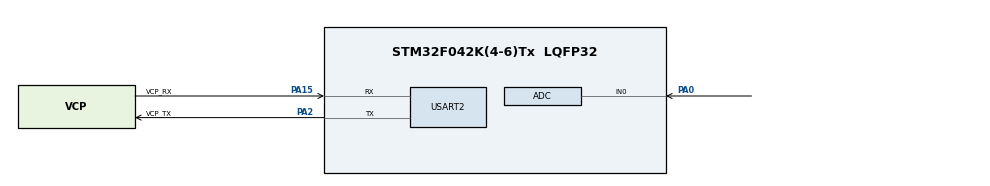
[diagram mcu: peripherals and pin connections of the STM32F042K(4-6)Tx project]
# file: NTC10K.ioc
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Dma.ADC.0.Direction=DMA_PERIPH_TO_MEMORY
Dma.ADC.0.Instance=DMA1_Channel1
Dma.ADC.0.MemDataAlignment=DMA_MDATAALIGN_HALFWORD
Dma.ADC.0.MemInc=DMA_MINC_ENABLE
Dma.ADC.0.Mode=DMA_CIRCULAR
Dma.ADC.0.PeriphDataAlignment=DMA_PDATAALIGN_HALFWORD
Dma.ADC.0.PeriphInc=DMA_PINC_DISABLE
Dma.ADC.0.Priority=DMA_PRIORITY_LOW
Dma.Request0=ADC
Mcu.Family=STM32F0
Mcu.Name=STM32F042K(4-6)Tx
Mcu.Package=LQFP32
NVIC.DMA1_Channel1_IRQn=true\:0\:0\:false\:false\:true\:false\:true
NVIC.TIM3_IRQn=true\:0\:0\:false\:false\:true\:true\:true
PA0.Mode=IN0
PA0.Signal=ADC_IN0
PA13.GPIO_Label=SWDIO
PA13.Mode=Serial_Wire
PA13.Signal=SYS_SWDIO
PA14.GPIO_Label=SWCLK
PA14.Mode=Serial_Wire
PA14.Signal=SYS_SWCLK
PA15.GPIO_Label=VCP_RX
PA15.Mode=Asynchronous
PA15.Signal=USART2_RX
PA2.GPIO_Label=VCP_TX
PA2.Mode=Asynchronous
PA2.Signal=USART2_TX
PF0-OSC_IN.GPIO_Label=MCO
PF0-OSC_IN.Mode=HSE-External-Clock-Source
PF0-OSC_IN.Signal=RCC_OSC_IN
ProjectManager.HeapSize=0x200
ProjectManager.StackSize=0x400
ProjectManager.TargetToolchain=STM32CubeIDE
TIM3.Period=1000-1
TIM3.Prescaler=800-1
USART2.VirtualMode-Asynchronous=VM_ASYNC
VP_TIM3_VS_ClockSourceINT.Mode=Internal
board=NUCLEO-F042K6

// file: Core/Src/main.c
/* USER CODE BEGIN Header */
/**
 ******************************************************************************
 * @file           : main.c
 * @brief          : Main program body
 ******************************************************************************
 * @attention
 *
 * <h2><center>&copy; Copyright (c) 2021 STMicroelectronics.
 * All rights reserved.</center></h2>
 *
 * This software component is licensed by ST under BSD 3-Clause license,
 * the "License"; You may not use this file except in compliance with the
 * License. You may obtain a copy of the License at:
 *                        opensource.org/licenses/BSD-3-Clause
 *
 ******************************************************************************
 */
/* USER CODE END Header */
#include "main.h"
#include "adc.h"
#include "dma.h"
#include "tim.h"
#include "usart.h"
#include "gpio.h"

/* USER CODE BEGIN Includes */
#include <math.h>
/* USER CODE END Includes */

/* USER CODE BEGIN PV */
/* adc vars */
uint16_t ADC_Raw[1];
/* ntc vars */
float Ntc_Tmp = 0;
uint16_t Ntc_R;
/* sheduler vars */
uint8_t Sch_100ms = 255;

/* R1 resistance */
#define NTC_UP_R 10000.0f
/* constants of Steinhart-Hart equation */
#define A 0.001111f
#define B 0.000237987f
#define C 0.000000065f
/* USER CODE END PV */

void SystemClock_Config(void);
/* USER CODE BEGIN PFP */
#define FILTER_SMA_ORDER 12
uint16_t Filter_Buffer[FILTER_SMA_ORDER] = { 0 };
/**
 * @brief Simple Moving Average (SMA) filter.
 * @note Before use define filter order.
 * @param[in] Input raw (unfiltered) value.
 * @retval Return filtered data.
 */
uint16_t Filter_SMA(uint16_t For_Filtered);
/* USER CODE END PFP */

/* USER CODE BEGIN 0 */
/**
 * @brief Simple Moving Average (SMA) filter.
 * @note Before use define filter order.
 * @param[in] Input raw (unfiltered) value.
 * @retval Return filtered data.
 */
uint16_t Filter_SMA(uint16_t For_Filtered)
{
    /* Load new value */
    Filter_Buffer[FILTER_SMA_ORDER - 1] = For_Filtered;
    /* For output value */
    uint32_t Output = 0;
    /* Sum */
    for (uint8_t i = 0; i < FILTER_SMA_ORDER; i++) {
        Output += Filter_Buffer[i];
    }
    /* Divide */
    Output /= FILTER_SMA_ORDER;
    /* Left Shift */
    for (uint8_t i = 0; i < FILTER_SMA_ORDER; i++) {
        Filter_Buffer[i] = Filter_Buffer[i + 1];
    }
    /* Return filtered value */
    return (uint16_t) Output;
}
/* USER CODE END 0 */

int main(void)
{

  /* MCU Configuration--------------------------------------------------------*/

  /* Reset of all peripherals, Initializes the Flash interface and the Systick. */
  HAL_Init();

  /* Configure the system clock */
  SystemClock_Config();

  /* Initialize all configured peripherals */
  MX_GPIO_Init();
  MX_DMA_Init();
  MX_ADC_Init();
  MX_USART2_UART_Init();
  MX_TIM3_Init();
  /* USER CODE BEGIN 2 */
    /* adc calibration */
    HAL_ADCEx_Calibration_Start(&hadc);
    /* adc dma start */
    HAL_ADC_Start_DMA(&hadc, (uint32_t*) ADC_Raw, 1);
    /* timer 3 (f=1Hz, T=1000ms start */
    HAL_TIM_Base_Start_IT(&htim3);
  /* USER CODE END 2 */

  /* Infinite loop */
  /* USER CODE BEGIN WHILE */
    while (1) {
        if (Sch_100ms) {
            /* get adc value */
            HAL_ADC_Start_IT(&hadc);
            /* filtering (sma) */
            uint16_t Ntc_Temp_ADC = Filter_SMA(ADC_Raw[0]);
            /* calc. ntc resistance */
            Ntc_R = ((NTC_UP_R) / ((4095.0 / Ntc_Temp_ADC) - 1));
            /* temp */
            float Ntc_Ln = log(Ntc_R);
            /* calc. temperature */
            Ntc_Tmp = (1.0 / (A + B * Ntc_Ln + C * Ntc_Ln * Ntc_Ln * Ntc_Ln))
                    - 273.15;
            /* nullify */
            Sch_100ms = 0;
        }
    /* USER CODE END WHILE */

    }
}

void SystemClock_Config(void)
{
  RCC_OscInitTypeDef RCC_OscInitStruct = {0};
  RCC_ClkInitTypeDef RCC_ClkInitStruct = {0};

  /** Initializes the RCC Oscillators according to the specified parameters
  * in the RCC_OscInitTypeDef structure.
  */
  RCC_OscInitStruct.OscillatorType = RCC_OSCILLATORTYPE_HSI|RCC_OSCILLATORTYPE_HSI14;
  RCC_OscInitStruct.HSIState = RCC_HSI_ON;
  RCC_OscInitStruct.HSI14State = RCC_HSI14_ON;
  RCC_OscInitStruct.HSICalibrationValue = RCC_HSICALIBRATION_DEFAULT;
  RCC_OscInitStruct.HSI14CalibrationValue = 16;
  RCC_OscInitStruct.PLL.PLLState = RCC_PLL_NONE;
  if (HAL_RCC_OscConfig(&RCC_OscInitStruct) != HAL_OK)
  {
    Error_Handler();
  }
  /** Initializes the CPU, AHB and APB buses clocks
  */
  RCC_ClkInitStruct.ClockType = RCC_CLOCKTYPE_HCLK|RCC_CLOCKTYPE_SYSCLK
                              |RCC_CLOCKTYPE_PCLK1;
  RCC_ClkInitStruct.SYSCLKSource = RCC_SYSCLKSOURCE_HSI;
  RCC_ClkInitStruct.AHBCLKDivider = RCC_SYSCLK_DIV1;
  RCC_ClkInitStruct.APB1CLKDivider = RCC_HCLK_DIV1;

  if (HAL_RCC_ClockConfig(&RCC_ClkInitStruct, FLASH_LATENCY_0) != HAL_OK)
  {
    Error_Handler();
  }
}

/* USER CODE BEGIN 4 */
void HAL_TIM_PeriodElapsedCallback(TIM_HandleTypeDef* htim)
{
    if (htim->Instance == TIM3) {
        /* set every 100ms */
        Sch_100ms = 255;
    }
}
/* USER CODE END 4 */

void Error_Handler(void)
{
    __disable_irq();
    while (1) {
    }
}

/************************ (C) COPYRIGHT STMicroelectronics *****END OF FILE****/
